AUTOSAR XML (schema 4-0-3)
standard types defined: Boolean, UInt16, UInt32
package /AUTOSAR_Platform/DataConstrs
  range DC_Boolean: raw 0..1
  range DC_UInt16: raw 0..65535
package /PATAC/MSM/ComponentTypes
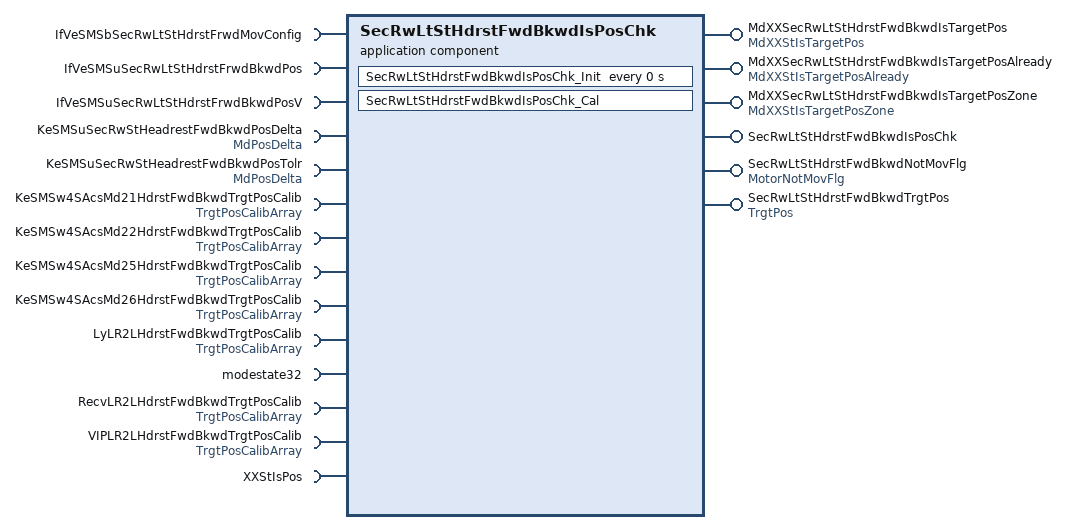
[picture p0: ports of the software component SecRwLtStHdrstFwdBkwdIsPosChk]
  application sw component type SecRwLtStHdrstFwdBkwdIsPosChk
    6 x provide port:
      MdXXSecRwLtStHdrstFwdBkwdIsTargetPos: nonqueued-sender-com-spec=data-element=MdXXStIsTargetPos/Val, provided-interface=MdXXStIsTargetPos
      MdXXSecRwLtStHdrstFwdBkwdIsTargetPosAlready: nonqueued-sender-com-spec=data-element=MdXXStIsTargetPosAlready/Val, provided-interface=MdXXStIsTargetPosAlready
      MdXXSecRwLtStHdrstFwdBkwdIsTargetPosZone: nonqueued-sender-com-spec=data-element=MdXXStIsTargetPosZone/Val, provided-interface=MdXXStIsTargetPosZone
      SecRwLtStHdrstFwdBkwdIsPosChk: server-com-spec{operation=Cal, queue-length=1}, provided-interface=SecRwLtStHdrstFwdBkwdIsPosChk
      SecRwLtStHdrstFwdBkwdNotMovFlg: nonqueued-sender-com-spec{data-element=MotorNotMovFlg/Val, init-value=0}, provided-interface=MotorNotMovFlg
      SecRwLtStHdrstFwdBkwdTrgtPos: nonqueued-sender-com-spec{data-element=TrgtPos/Val, init-value=4095}, provided-interface=TrgtPos
    14 x require port:
      IfVeSMSbSecRwLtStHdrstFrwdMovConfig: nonqueued-receiver-com-spec{data-element=IfVeSMSbSecRwLtStHdrstFrwdMovConfig/Val, filter=data-filter-type=ALWAYS, init-value=1}, required-interface=IfVeSMSbSecRwLtStHdrstFrwdMovConfig
      IfVeSMSuSecRwLtStHdrstFrwdBkwdPos: nonqueued-receiver-com-spec{data-element=IfVeSMSuSecRwLtStHdrstFrwdBkwdPos/Val, filter=data-filter-type=ALWAYS, init-value=0}, required-interface=IfVeSMSuSecRwLtStHdrstFrwdBkwdPos
      IfVeSMSuSecRwLtStHdrstFrwdBkwdPosV: nonqueued-receiver-com-spec{data-element=IfVeSMSuSecRwLtStHdrstFrwdBkwdPosV/Val, filter=data-filter-type=ALWAYS, init-value=0}, required-interface=IfVeSMSuSecRwLtStHdrstFrwdBkwdPosV
      KeSMSuSecRwStHeadrestFwdBkwdPosDelta: parameter-require-com-spec{init-value=150, parameter=Val}, required-interface=MdPosDelta
      KeSMSuSecRwStHeadrestFwdBkwdPosTolr: parameter-require-com-spec{init-value=150, parameter=Val}, required-interface=MdPosDelta
      KeSMSw4SAcsMd21HdrstFwdBkwdTrgtPosCalib: nonqueued-receiver-com-spec{data-element=TrgtPosArray, filter=data-filter-type=ALWAYS, init-value=[4095, 4095, 4095]}, required-interface=TrgtPosCalibArray
      KeSMSw4SAcsMd22HdrstFwdBkwdTrgtPosCalib: nonqueued-receiver-com-spec{data-element=TrgtPosArray, filter=data-filter-type=ALWAYS, init-value=[4095, 4095, 4095]}, required-interface=TrgtPosCalibArray
      KeSMSw4SAcsMd25HdrstFwdBkwdTrgtPosCalib: nonqueued-receiver-com-spec{data-element=TrgtPosArray, filter=data-filter-type=ALWAYS, init-value=[4095, 4095, 4095]}, required-interface=TrgtPosCalibArray
      KeSMSw4SAcsMd26HdrstFwdBkwdTrgtPosCalib: nonqueued-receiver-com-spec{data-element=TrgtPosArray, filter=data-filter-type=ALWAYS, init-value=[4095, 4095, 4095]}, required-interface=TrgtPosCalibArray
      LyLR2LHdrstFwdBkwdTrgtPosCalib: nonqueued-receiver-com-spec{data-element=TrgtPosArray, filter=data-filter-type=ALWAYS, init-value=[4095, 4095, 4095]}, required-interface=TrgtPosCalibArray
      modestate32: nonqueued-receiver-com-spec{data-element=modestate32/Val, filter=data-filter-type=ALWAYS, init-value=0}, required-interface=modestate32
      RecvLR2LHdrstFwdBkwdTrgtPosCalib: nonqueued-receiver-com-spec{data-element=TrgtPosArray, filter=data-filter-type=ALWAYS, init-value=[4095, 4095, 4095]}, required-interface=TrgtPosCalibArray
      VIPLR2LHdrstFwdBkwdTrgtPosCalib: nonqueued-receiver-com-spec{data-element=TrgtPosArray, filter=data-filter-type=ALWAYS, init-value=[4095, 4095, 4095]}, required-interface=TrgtPosCalibArray
      XXStIsPos: client-com-spec=Get, required-interface=XXStIsPos
    behavior SecRwLtStHdrstFwdBkwdIsPosChk_InternalBehavior
      operation invoked event OIT_SecRwLtStHdrstFwdBkwdIsPosChk_Cal_SecRwLtStHdrstFwdBkwdIsPosChk_Cal: start-on-event=SecRwLtStHdrstFwdBkwdIsPosChk_Cal, operation=SecRwLtStHdrstFwdBkwdIsPosChk.Cal
      timing event SecRwLtStHdrstFwdBkwdIsPosChk_InitEvent: start-on-event=SecRwLtStHdrstFwdBkwdIsPosChk_Init, period=0
      runnable SecRwLtStHdrstFwdBkwdIsPosChk_Cal
        data-receive-point-by-arguments:
          11 x access:
            REC_IfVeSMSbSecRwLtStHdrstFrwdMovConfig_Val: accessed-variable=IfVeSMSbSecRwLtStHdrstFrwdMovConfig.Val
            REC_IfVeSMSuSecRwLtStHdrstFrwdBkwdPos_Val: accessed-variable=IfVeSMSuSecRwLtStHdrstFrwdBkwdPos.Val
            REC_IfVeSMSuSecRwLtStHdrstFrwdBkwdPosV_Val: accessed-variable=IfVeSMSuSecRwLtStHdrstFrwdBkwdPosV.Val
            REC_KeSMSw4SAcsMd21HdrstFwdBkwdTrgtPosCalib_TrgtPosArray: accessed-variable=KeSMSw4SAcsMd21HdrstFwdBkwdTrgtPosCalib.TrgtPosArray
            REC_KeSMSw4SAcsMd22HdrstFwdBkwdTrgtPosCalib_TrgtPosArray: accessed-variable=KeSMSw4SAcsMd22HdrstFwdBkwdTrgtPosCalib.TrgtPosArray
            REC_KeSMSw4SAcsMd25HdrstFwdBkwdTrgtPosCalib_TrgtPosArray: accessed-variable=KeSMSw4SAcsMd25HdrstFwdBkwdTrgtPosCalib.TrgtPosArray
            REC_KeSMSw4SAcsMd26HdrstFwdBkwdTrgtPosCalib_TrgtPosArray: accessed-variable=KeSMSw4SAcsMd26HdrstFwdBkwdTrgtPosCalib.TrgtPosArray
            REC_LyLR2LHdrstFwdBkwdTrgtPosCalib_TrgtPosArray: accessed-variable=LyLR2LHdrstFwdBkwdTrgtPosCalib.TrgtPosArray
            REC_modestate32_Val: accessed-variable=modestate32.Val
            REC_RecvLR2LHdrstFwdBkwdTrgtPosCalib_TrgtPosArray: accessed-variable=RecvLR2LHdrstFwdBkwdTrgtPosCalib.TrgtPosArray
            REC_VIPLR2LHdrstFwdBkwdTrgtPosCalib_TrgtPosArray: accessed-variable=VIPLR2LHdrstFwdBkwdTrgtPosCalib.TrgtPosArray
        data-send-points:
          5 x access:
            SEND_MdXXSecRwLtStHdrstFwdBkwdIsTargetPos_Val: accessed-variable=MdXXSecRwLtStHdrstFwdBkwdIsTargetPos.Val
            SEND_MdXXSecRwLtStHdrstFwdBkwdIsTargetPosAlready_Val: accessed-variable=MdXXSecRwLtStHdrstFwdBkwdIsTargetPosAlready.Val
            SEND_MdXXSecRwLtStHdrstFwdBkwdIsTargetPosZone_Val: accessed-variable=MdXXSecRwLtStHdrstFwdBkwdIsTargetPosZone.Val
            SEND_SecRwLtStHdrstFwdBkwdNotMovFlg_Val: accessed-variable=SecRwLtStHdrstFwdBkwdNotMovFlg.Val
            SEND_SecRwLtStHdrstFwdBkwdTrgtPos_Val: accessed-variable=SecRwLtStHdrstFwdBkwdTrgtPos.Val
        parameter access PA_KeSMSuSecRwStHeadrestFwdBkwdPosDelta_Val: accessed-parameter=KeSMSuSecRwStHeadrestFwdBkwdPosDelta.Val
        parameter access PA_KeSMSuSecRwStHeadrestFwdBkwdPosTolr_Val: accessed-parameter=KeSMSuSecRwStHeadrestFwdBkwdPosTolr.Val
        sync call SC_XXStIsPos_Get: operation=XXStIsPos.Get, timeout=0
      runnable SecRwLtStHdrstFwdBkwdIsPosChk_Init
        parameter access PA_KeSMSuSecRwStHeadrestFwdBkwdPosDelta_Val: accessed-parameter=KeSMSuSecRwStHeadrestFwdBkwdPosDelta.Val
        parameter access PA_KeSMSuSecRwStHeadrestFwdBkwdPosTolr_Val: accessed-parameter=KeSMSuSecRwStHeadrestFwdBkwdPosTolr.Val
  swc implementation SecRwLtStHdrstFwdBkwdIsPosChk_Implementation: behavior=SecRwLtStHdrstFwdBkwdIsPosChk_InternalBehavior
    code-descriptors:
      code Default: artifact-descriptors=autosar-engineering-object={short-label=Default, category=SWSRC}
package /PATAC/MSM/ModeAdjust/CalPortInterface
  parameter interface MdPosDelta
    parameter data prototype Val: sw-calibration-access=READ-WRITE, type=UInt16
package /PATAC/MSM/ModeAdjust/DataType
  impl type TrgtPosCalibArray: category=ARRAY, sw-calibration-access=READ-ONLY, type-emitter=RTE  # 0:pos 1:max 2:min
    element Element: array-size=3, array-size-semantics=FIXED-SIZE, implementation-data-type=UInt16, invalid-value=0
package /PATAC/MSM/ModeAdjust/PortInterface
  client server interface SecRwLtStHdrstFwdBkwdIsPosChk
    operation Cal
  client server interface XXStIsPos
    operation Get
      8 x arg, all with server-argument-impl-policy=USE-ARGUMENT-TYPE:
        PosV: type=DataTypes/Boolean, direction=IN
        Pos: type=UInt16, direction=IN
        CalibArray: type=TrgtPosCalibArray, direction=IN
        Delta: type=UInt16, direction=IN
        Tolr: type=UInt16, direction=IN
        IsPos: type=DataTypes/Boolean, direction=OUT
        IsPosZone: type=DataTypes/Boolean, direction=OUT
        IsPosAlready: type=DataTypes/Boolean, direction=OUT
  7 x sender receiver interface:
    IfVeSMSbSecRwLtStHdrstFrwdMovConfig: invalidation-policy{data-element=IfVeSMSbSecRwLtStHdrstFrwdMovConfig/Val, handle-invalid=DONT-INVALIDATE}
      data Val: type=Implementation/Boolean
    MdXXStIsTargetPos: invalidation-policy{data-element=MdXXStIsTargetPos/Val, handle-invalid=DONT-INVALIDATE}
      data Val: type=UInt32
    MdXXStIsTargetPosAlready: invalidation-policy{data-element=MdXXStIsTargetPosAlready/Val, handle-invalid=DONT-INVALIDATE}
      data Val: type=UInt32
    MdXXStIsTargetPosZone: invalidation-policy{data-element=MdXXStIsTargetPosZone/Val, handle-invalid=DONT-INVALIDATE}
      data Val: type=UInt32
    modestate32: invalidation-policy{data-element=modestate32/Val, handle-invalid=DONT-INVALIDATE}
      data Val: type=UInt32
    MotorNotMovFlg: invalidation-policy{data-element=MotorNotMovFlg/Val, handle-invalid=DONT-INVALIDATE}
      data Val: type=Implementation/Boolean
    TrgtPosCalibArray: invalidation-policy{data-element=TrgtPosArray, handle-invalid=DONT-INVALIDATE}
      data TrgtPosArray: type=TrgtPosCalibArray  # 0:Pos 1:Max 2:Min
package /PATAC/MSM/PortInterfaces
  sender receiver interface IfVeSMSuSecRwLtStHdrstFrwdBkwdPos: invalidation-policy{data-element=IfVeSMSuSecRwLtStHdrstFrwdBkwdPos/Val, handle-invalid=DONT-INVALIDATE}
    data Val: type=UInt16
  sender receiver interface IfVeSMSuSecRwLtStHdrstFrwdBkwdPosV: invalidation-policy{data-element=IfVeSMSuSecRwLtStHdrstFrwdBkwdPosV/Val, handle-invalid=DONT-INVALIDATE}
    data Val: type=Implementation/Boolean
  sender receiver interface TrgtPos: invalidation-policy{data-element=TrgtPos/Val, handle-invalid=DONT-INVALIDATE}
    data Val: type=UInt16
